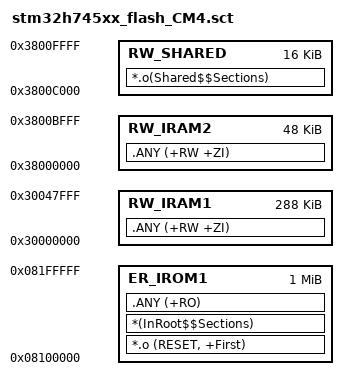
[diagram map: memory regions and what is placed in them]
; *************************************************************
; *** Scatter-Loading Description File generated by uVision ***
; *************************************************************

LR_IROM1 0x08100000 0x00100000  {    ; load region size_region
  ER_IROM1 0x08100000 0x00100000  {  ; load address = execution address
    *.o (RESET, +First)
    *(InRoot$$Sections)
    .ANY (+RO)
  }
  RW_IRAM1 0x30000000 0x00048000 {  ; RW data (SRAM1, SRAM2, SRAM3, 288K)
    .ANY (+RW +ZI)
  }
  RW_IRAM2 0x38000000 0x0000C000 { ; RW Resources manager (SRAM4 48K)
    .ANY (+RW +ZI)
  }
  RW_SHARED 0x3800C000 0x00004000 { ; RW shared memory (SRAM4 16K)
    *.o(Shared$$Sections)
  }
}
